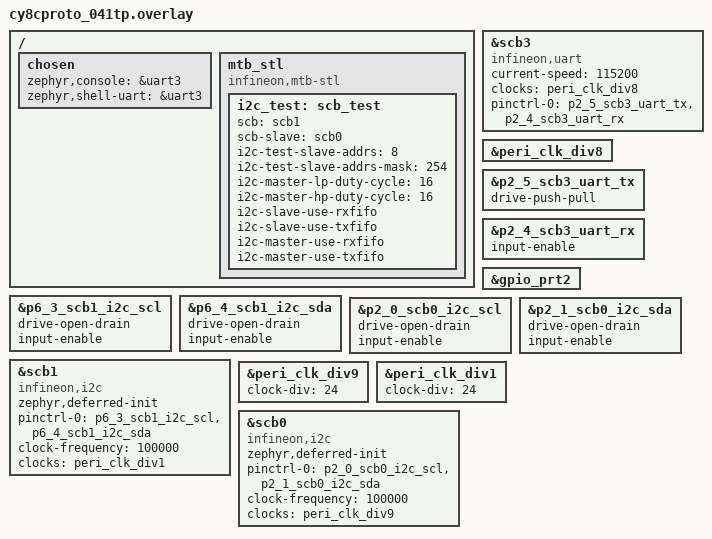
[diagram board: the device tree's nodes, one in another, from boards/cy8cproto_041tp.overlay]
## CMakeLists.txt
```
# SPDX-License-Identifier: Apache-2.0

cmake_minimum_required(VERSION 3.20.0)

find_package(Zephyr REQUIRED HINTS $ENV{ZEPHYR_BASE})
project(post_i2c_mtb_stl_sample)

target_sources(app PRIVATE src/main.c)
```

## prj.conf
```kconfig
# POST subsystem
CONFIG_POST=y
CONFIG_POST_VENDOR_MTB_STL=y
CONFIG_POST_SHELL=y
CONFIG_POST_HALT_ON_FAILURE=n
CONFIG_POST_RUNTIME_TESTS=y

# Enable I2C MTB-STL tests
CONFIG_POST_MTB_STL_I2C=y

# Zephyr driver configs
CONFIG_I2C=y

# Shell support
CONFIG_SHELL=y

# Logging
CONFIG_LOG=y
CONFIG_POST_LOG_LEVEL=4
```

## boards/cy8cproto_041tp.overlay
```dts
/*
 * Copyright (c) 2025 Infineon Technologies AG,
 * or an affiliate of Infineon Technologies AG.
 *
 * SPDX-License-Identifier: Apache-2.0
 */

uart3: &scb3 {
	compatible = "infineon,uart";
	status = "okay";
	current-speed = <115200>;
	clocks = <&peri_clk_div8>;
	pinctrl-0 = <&p2_5_scb3_uart_tx &p2_4_scb3_uart_rx>;
	pinctrl-names = "default";
};

&peri_clk_div8 {
	status = "okay";
};

&p2_5_scb3_uart_tx {
	drive-push-pull;
};

&p2_4_scb3_uart_rx {
	input-enable;
};

&gpio_prt2 {
	status = "okay";
};

/ {
	chosen {
		zephyr,console = &uart3;
		zephyr,shell-uart = &uart3;
	};
};

/* Board-level pinctrl: I2C drive modes for SCB1 (application master) */
&p6_3_scb1_i2c_scl {
	drive-open-drain;
	input-enable;
};

&p6_4_scb1_i2c_sda {
	drive-open-drain;
	input-enable;
};

/* Board-level pinctrl: I2C drive modes for SCB0 (test slave fixture) */
&p2_0_scb0_i2c_scl {
	drive-open-drain;
	input-enable;
};

&p2_1_scb0_i2c_sda {
	drive-open-drain;
	input-enable;
};

/* Application: SCB1 as I2C master — this is the device under test */
i2c1: &scb1 {
	compatible = "infineon,i2c";
	status = "okay";
	/* Start the normal driver only after PASS and cleanup. */
	zephyr,deferred-init;
	pinctrl-0 = <&p6_3_scb1_i2c_scl &p6_4_scb1_i2c_sda>;
	pinctrl-names = "default";
	clock-frequency = <100000>;
	clocks = <&peri_clk_div1>;
	#address-cells = <1>;
	#size-cells = <0>;
};

/*
 * Test fixture: SCB0 as I2C slave, wired to SCB1's bus.
 * Its normal Zephyr driver is initialized only after POST passes.
 * Both clock dividers initialize at boot: 48 MHz / 24 = 2 MHz for POST.
 */
&peri_clk_div9 {
	status = "okay";
	clock-div = <24>;
};

&peri_clk_div1 {
	status = "okay";
	clock-div = <24>;
};

i2c0: &scb0 {
	/delete-property/ current-speed;

	compatible = "infineon,i2c";
	status = "okay";
	zephyr,deferred-init;
	pinctrl-0 = <&p2_0_scb0_i2c_scl &p2_1_scb0_i2c_sda>;
	pinctrl-names = "default";
	clock-frequency = <100000>;
	clocks = <&peri_clk_div9>;
	#address-cells = <1>;
	#size-cells = <0>;
};

/ {
	mtb_stl: mtb_stl {
		compatible = "infineon,mtb-stl";
		status = "okay";

		/*
		 * I2C master-slave test.
		 * DUT: &scb1 (app's I2C master)
		 * Fixture: &scb0 (slave, wired to same bus)
		 *
		 * SelfTest_I2C_SCB(master_base, ..., slave_base, ...).
		 */
		i2c_test: scb_test {
			scb = <&scb1>;
			scb-slave = <&scb0>;
			i2c-test-slave-addrs = <8>;
			i2c-test-slave-addrs-mask = <254>;
			i2c-master-lp-duty-cycle = <16>;
			i2c-master-hp-duty-cycle = <16>;
			i2c-slave-use-rxfifo;
			i2c-slave-use-txfifo;
			i2c-master-use-rxfifo;
			i2c-master-use-txfifo;
		};
	};
};
```

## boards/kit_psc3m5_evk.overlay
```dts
/*
 * SPDX-FileCopyrightText: Copyright (c) 2026 Infineon Technologies AG,
 * SPDX-FileCopyrightText: or an affiliate of Infineon Technologies AG. All rights reserved.
 *
 * SPDX-License-Identifier: Apache-2.0
 */

/*
 * Board Requirements:
 * - I2C master-slave test: wire the two SCBs onto one bus and fit bus
 *   pull-ups (typ. 2.2 kOhm - 4.7 kOhm to VDDD) if the chosen header pins do
 *   not already have them (all connections on the J5 expansion header):
 *     connect master SCL (P7.0, J5.18) <-> slave SCL (P8.1, J5.13)
 *     connect master SDA (P7.1, J5.14) <-> slave SDA (P8.3, J5.17)
 */

#include <zephyr/dt-bindings/gpio/gpio.h>

/* Both I2C drivers remain deferred until POST passes and cleans up. */
/* Application: scb2 as I2C master - this is the device under test */
i2c2: &scb2 {
	compatible = "infineon,i2c";
	status = "okay";
	zephyr,deferred-init;
	clock-frequency = <100000>;
	clocks = <&peri0_group4_16bit_0>;
	pinctrl-0 = <&p7_0_scb2_i2c_scl &p7_1_scb2_i2c_sda>;
	pinctrl-names = "default";
	#address-cells = <1>;
	#size-cells = <0>;
};

/* Test fixture: scb5 as I2C slave, wired to scb2's bus */
i2c5: &scb5 {
	compatible = "infineon,i2c";
	status = "okay";
	zephyr,deferred-init;
	clock-frequency = <100000>;
	clocks = <&peri0_group6_16_5bit_0>;
	pinctrl-0 = <&p8_1_scb5_i2c_scl &p8_3_scb5_i2c_sda>;
	pinctrl-names = "default";
	#address-cells = <1>;
	#size-cells = <0>;
};

&p7_0_scb2_i2c_scl {
	bias-pull-up;
	input-enable;
};

&p7_1_scb2_i2c_sda {
	bias-pull-up;
	input-enable;
};

&p8_1_scb5_i2c_scl {
	bias-pull-up;
	input-enable;
};

&p8_3_scb5_i2c_sda {
	bias-pull-up;
	input-enable;
};

/* Boot clock setup supplies 2 MHz before either deferred I2C driver runs. */
&peri0_group4_16bit_0 {
	status = "okay";
	clock-div = <40>; /* Board-configured HF2: 80 MHz / 40. */
};

&peri0_group6_16_5bit_0 {
	status = "okay";
	clock-div = <40>; /* HF4: 80 MHz / 40. */
};

/* SCB5 uses HF4; select 240 MHz / 3. HF2 is configured in the board DTS. */
&clk_hf4 {
	source-path = <IFX_CLK_HF_IN_CLKPATH2>;
	clock-div = <IFX_CLK_HF_DIVIDE_BY_3>;
	status = "okay";
};

/ {
	mtb_stl: mtb_stl {
		compatible = "infineon,mtb-stl";
		status = "okay";

		i2c_test: scb_test {
			scb = <&scb2>;
			scb-slave = <&scb5>;
			i2c-test-slave-addrs = <8>;
			i2c-test-slave-addrs-mask = <254>;
			i2c-master-lp-duty-cycle = <16>;
			i2c-master-hp-duty-cycle = <16>;
			i2c-slave-use-rxfifo;
			i2c-slave-use-txfifo;
			i2c-master-use-rxfifo;
			i2c-master-use-txfifo;
		};
	};
};
```

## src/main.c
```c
/*
 * Copyright (c) 2026 Aerlync Labs Inc.
 * SPDX-License-Identifier: Apache-2.0
 */

#include <zephyr/kernel.h>
#include <zephyr/post/post.h>
#include <zephyr/shell/shell.h>
#include <zephyr/logging/log.h>

LOG_MODULE_REGISTER(post_i2c_sample, LOG_LEVEL_INF);

int main(void)
{
	uint32_t passed;
	uint32_t failed;
	uint32_t skipped;

	printk("\n");
	printk("====================================\n");
	printk("Starting I2C POST sample application\n");
	printk("====================================\n");
	printk("\n");

	LOG_INF("POST subsystem initialized");
	LOG_INF("MTB-STL tests registered during boot");

	post_get_summary(&passed, &failed, &skipped);
	printk("POST summary: %u passed, %u failed, %u skipped\n", passed, failed, skipped);

	printk("Available shell commands:\n");
	printk("  post list   - List all registered POST tests\n");
	printk("  post run    - Run runtime POST tests\n");
	printk("  post status - Show POST test results\n");
	printk("\n");

	/* Application main loop */
	while (1) {
		k_sleep(K_SECONDS(5));
		LOG_DBG("Application running...");
	}

	return 0;
}
```
